# nrf9120_mlm1_modem register map
Vendor: Nordic Semiconductor; Series: nrf91; File version: 1
CPU: CM4 r0p1, little endian, MPU, no FPU, 3 interrupt priority bits
Registers are 32-bit, read-write, reset 0x0 unless marked. A register's access mark holds for its fields unless they carry their own. Offsets are from the block's base; [hi:lo] are bit positions; lines under a group give offsets from that group; {n}, {i} and the like mark numbered series; 'fields as' and 'values as' point back to an identical list.

## TRACEANDDEBUG
Base 0xE0080000
0x00 STARTCLOCKS wo — Start all Trace and Debug clocks.
  [0] STARTCLOCKS
    1=STARTCLOCKS (Start all Trace and Debug clocks.)
0x04 STOPCLOCKS wo — Stop all Trace and Debug clocks.
  [0] STOPCLOCKS
    1=STOPCLOCKS (Stop all Trace and Debug clocks.)
0x60 TASKZEROPENALTY_PCP_3 wo — TaskZeroPenalty register for PCP 3
  [0] ZERO_PENALTY
    1=Set_Zero_Penalty
0x64 TASKFULLPENALTY_PCP_3 wo — TaskFullPenalty register for PCP 3
  [0] FULL_PENALTY
    1=Set_Full_Penalty
0x68 TASKZEROPENALTY_PCP_2 wo — TaskZeroPenalty register for PCP 2
  [0] ZERO_PENALTY
    1=Set_Zero_Penalty
0x6C TASKFULLPENALTY_PCP_2 wo — TaskFullPenalty register for PCP 2
  [0] FULL_PENALTY
    1=Set_Full_Penalty
0x70 TASKZEROPENALTY_PCP_1 wo — TaskZeroPenalty register for PCP 1
  [0] ZERO_PENALTY
    1=Set_Zero_Penalty
0x74 TASKFULLPENALTY_PCP_1 wo — TaskFullPenalty register for PCP 1
  [0] FULL_PENALTY
    1=Set_Full_Penalty
0x78 TASKZEROPENALTY_PCP_0 wo — TaskZeroPenalty register for PCP 0
  [0] ZERO_PENALTY
    1=Set_Zero_Penalty
0x7C TASKFULLPENALTY_PCP_0 wo — TaskFullPenalty register for PCP 0
  [0] FULL_PENALTY
    1=Set_Full_Penalty
0x500 ENABLEDEBUG — Master enable for PSEL.TraceData[3:0] and PSEL.TraceClk signals
  [0] ENABLEDEBUG
    1=ENABLEDEBUG (Master enable for PSEL.TraceData[3:0] and PSEL.TraceClk signals)
0x504 PSEL group — Unspecified
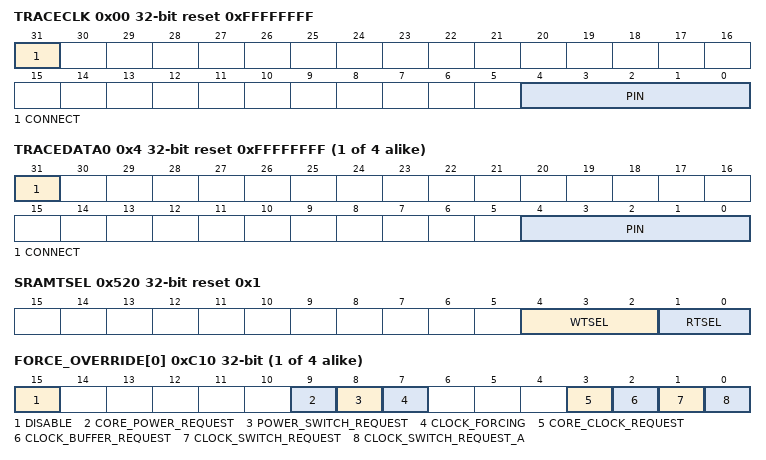
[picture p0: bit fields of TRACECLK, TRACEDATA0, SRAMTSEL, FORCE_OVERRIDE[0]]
  0x00 TRACECLK reset 0xFFFFFFFF — Pin number configuration for TraceClk signal
    [31] CONNECT — Connection
      1=Disconnected; 0=Connected
    [4:0] PIN — Pin number
  {0x4+4j} TRACEDATA{j} reset 0xFFFFFFFF (j=0..3) — Pin number configuration for TraceData{j} signal
    fields as PSEL.TRACECLK
0x518 TRACEPORTSPEED — Trace port speed selection
  [1:0] TRACEPORTSPEED — Speed of Trace Port clock. Note that the TRACECLK pin will output this clock divided by two.
    0=32 MHz Trace Port clock (TRACECLK = 16 MHz); 1=16 MHz Trace Port clock (TRACECLK = 8 MHz); 2=8 MHz Trace Port clock (TRACECLK = 4 MHz); 3=4 MHz Trace Port clock (TRACECLK = 2 MHz)
0x51C SWOSEL — Connect the SWO to the TPIU TRACEDATA[0]
  [0] SWOSEL
    0=TRACEDATA0SEL (Connect the TRACEDATA[0] to the TPIU TRACEDATA[0]); 1=SWOSEL (Connect the SWO to the TPIU TRACEDATA[0])
0x520 SRAMTSEL reset 0x1 — Timing control values for TSMC RAMs
  [4:2] WTSEL — Write cycle timing selection
  [1:0] RTSEL — Read cycle timing selection
{0xC00+4i} PENALTY_REG[{i}] (i=0..3) — Description collection: Penalty register for PCP n
  [1:0] PENALTY — Penalty Level
    0=Full ((Auto 0) Full penalty)); 1=Semi1 ((Auto 1) Semi (power on, clock off)); 2=Semi0 ((Auto 2) Semi (power on, clock core on, clock buffer off)); 3=Zero ((Auto 3) Zero penalty)
{0xC10+4i} FORCE_OVERRIDE[{i}] (i=0..3) — Description collection: Force override register for PCP n
  [15] DISABLE
    0=Disable (all forcing disabled); 1=Enable (all forcing enabled)
  [9] CORE_POWER_REQUEST
    0=REQ0 (powerRequest.core = 0); 1=REQ1 (powerRequest.core = 1)
  [8] POWER_SWITCH_REQUEST
    0=REQ0 (powerRequest.switch = 0); 1=REQ1 (powerRequest.switch = 1)
  [7] CLOCK_FORCING
    0=FORCE0 (All clock forcing disabled); 1=FORCE1 (All clock forcing enabled)
  [3] CORE_CLOCK_REQUEST
    0=REQ0 (clockRequest.core = 0); 1=REQ1 (clockRequest.core = 1)
  [2] CLOCK_BUFFER_REQUEST
    0=REQ0 (clockRequest.buff = 0); 1=REQ1 (clockRequest.buff = 1)
  [1] CLOCK_SWITCH_REQUEST
    0=REQ0 (clockRequest.switch = 0); 1=REQ1 (clockRequest.switch = 1)
  [0] CLOCK_SWITCH_REQUEST_A
    0=REQ0 (clockRequest.switch_a = 0); 1=REQ1 (clockRequest.switch_a = 1)
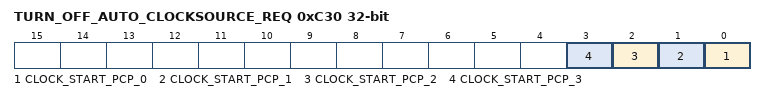
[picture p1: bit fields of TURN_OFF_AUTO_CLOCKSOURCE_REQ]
0xC30 TURN_OFF_AUTO_CLOCKSOURCE_REQ — Turn of the automatic clock request.
  [n] CLOCK_START_PCP_{n} (n=0..3)
    0=NORMAL_PCP_{n} (normal clock start for PCP {n}); 1=OFF_PCP_{n} (turn off normal clock start for PCP {n})
